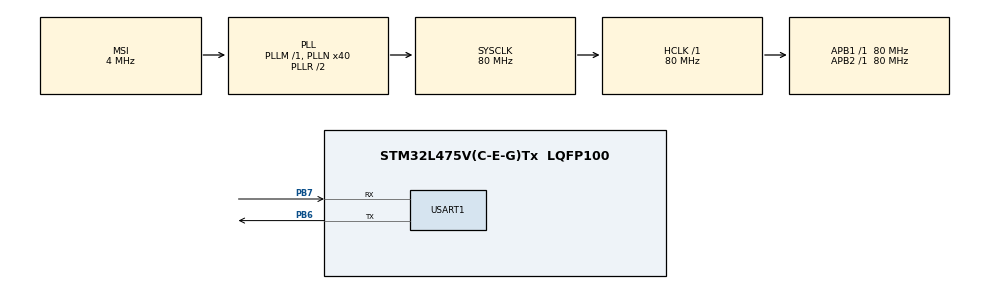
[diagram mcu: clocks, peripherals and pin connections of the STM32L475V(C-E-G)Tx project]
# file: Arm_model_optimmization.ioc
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Mcu.Family=STM32L4
Mcu.Name=STM32L475V(C-E-G)Tx
Mcu.Package=LQFP100
NVIC.PriorityGroup=NVIC_PRIORITYGROUP_4
PA13\ (JTMS-SWDIO).Mode=Trace_Asynchronous_SW
PA13\ (JTMS-SWDIO).Signal=SYS_JTMS-SWDIO
PA14\ (JTCK-SWCLK).Mode=Trace_Asynchronous_SW
PA14\ (JTCK-SWCLK).Signal=SYS_JTCK-SWCLK
PB3\ (JTDO-TRACESWO).Mode=Trace_Asynchronous_SW
PB3\ (JTDO-TRACESWO).Signal=SYS_JTDO-SWO
PB6.Mode=Asynchronous
PB6.Signal=USART1_TX
PB7.Mode=Asynchronous
PB7.Signal=USART1_RX
PH0-OSC_IN\ (PH0).Mode=HSE-External-Oscillator
PH0-OSC_IN\ (PH0).Signal=RCC_OSC_IN
PH1-OSC_OUT\ (PH1).Mode=HSE-External-Oscillator
PH1-OSC_OUT\ (PH1).Signal=RCC_OSC_OUT
ProjectManager.HeapSize=0x800
ProjectManager.StackSize=0x800
ProjectManager.TargetToolchain=STM32CubeIDE
RCC.ADCFreq_Value=48000000
RCC.AHBFreq_Value=80000000
RCC.APB1Freq_Value=80000000
RCC.APB1TimFreq_Value=80000000
RCC.APB2Freq_Value=80000000
RCC.APB2TimFreq_Value=80000000
RCC.CortexFreq_Value=80000000
RCC.HCLKFreq_Value=80000000
RCC.HSE_VALUE=8000000
RCC.HSI_VALUE=16000000
RCC.MSI_VALUE=4000000
RCC.PLLN=40
RCC.PLLSAI1N=24
RCC.SYSCLKFreq_VALUE=80000000
RCC.SYSCLKSource=RCC_SYSCLKSOURCE_PLLCLK
RCC.USBFreq_Value=48000000
RCC.VCOOutputFreq_Value=160000000
STMicroelectronics.X-CUBE-AI.10.2.0.ActivationBufferSizeList=57044
STMicroelectronics.X-CUBE-AI.10.2.0.ActivationBuffers=pool0
STMicroelectronics.X-CUBE-AI.10.2.0.ActivationNames=pool0
STMicroelectronics.X-CUBE-AI.10.2.0.ActivationSizes=AI_NETWORK_DATA_ACTIVATION_1_SIZE
STMicroelectronics.X-CUBE-AI.10.2.0.ApplicationCcDeviceJjApplication=SystemPerformance
STMicroelectronics.X-CUBE-AI.10.2.0.BSP.number=1
STMicroelectronics.X-CUBE-AI.10.2.0.HeapSize=0x800
STMicroelectronics.X-CUBE-AI.10.2.0.InternalRamActivationBufferMaxSize=AI_NETWORK_DATA_ACTIVATIONS_SIZE
STMicroelectronics.X-CUBE-AI.10.2.0.LatestDirectoryUsed-4751c7fde2dbf1a05914dd5fdbb3a8e7d666a6bb74f4718387b990bd9b3825d4=D\:\\1vidamuyarchi\\arm_example
STMicroelectronics.X-CUBE-AI.10.2.0.MaximumNumberOfInputLayer=1
STMicroelectronics.X-CUBE-AI.10.2.0.MaximumNumberOfOutputLayer=1
STMicroelectronics.X-CUBE-AI.10.2.0.MaximumSizeOfInputLayer=1
STMicroelectronics.X-CUBE-AI.10.2.0.MaximumSizeOfOutputLayer=1
STMicroelectronics.X-CUBE-AI.10.2.0.ModelActualCompression-4751c7fde2dbf1a05914dd5fdbb3a8e7d666a6bb74f4718387b990bd9b3825d4=0.0
STMicroelectronics.X-CUBE-AI.10.2.0.ModelCompression-4751c7fde2dbf1a05914dd5fdbb3a8e7d666a6bb74f4718387b990bd9b3825d4=None
STMicroelectronics.X-CUBE-AI.10.2.0.ModelFlashOccupation-4751c7fde2dbf1a05914dd5fdbb3a8e7d666a6bb74f4718387b990bd9b3825d4=110508
STMicroelectronics.X-CUBE-AI.10.2.0.ModelHashList=4751c7fde2dbf1a05914dd5fdbb3a8e7d666a6bb74f4718387b990bd9b3825d4
STMicroelectronics.X-CUBE-AI.10.2.0.ModelKind-4751c7fde2dbf1a05914dd5fdbb3a8e7d666a6bb74f4718387b990bd9b3825d4=TFLITE
STMicroelectronics.X-CUBE-AI.10.2.0.ModelMacc-4751c7fde2dbf1a05914dd5fdbb3a8e7d666a6bb74f4718387b990bd9b3825d4=2737536
STMicroelectronics.X-CUBE-AI.10.2.0.ModelName-4751c7fde2dbf1a05914dd5fdbb3a8e7d666a6bb74f4718387b990bd9b3825d4=network
STMicroelectronics.X-CUBE-AI.10.2.0.ModelNameList=network
STMicroelectronics.X-CUBE-AI.10.2.0.ModelRamOccupation-4751c7fde2dbf1a05914dd5fdbb3a8e7d666a6bb74f4718387b990bd9b3825d4=57044
STMicroelectronics.X-CUBE-AI.10.2.0.ModelStructureFile-4751c7fde2dbf1a05914dd5fdbb3a8e7d666a6bb74f4718387b990bd9b3825d4=/D\:/1vidamuyarchi/arm_example/kws_ref_model_float32.tflite
STMicroelectronics.X-CUBE-AI.10.2.0.ModelType-4751c7fde2dbf1a05914dd5fdbb3a8e7d666a6bb74f4718387b990bd9b3825d4=STM32Cube.AI MCU runtime
STMicroelectronics.X-CUBE-AI.10.2.0.ReadyForCodeGeneration=true
STMicroelectronics.X-CUBE-AI.10.2.0.StackSize=0x800
STMicroelectronics.X-CUBE-AI.10.2.0.WorkingBufferStartAddrList=0xFFFFFFFF
STMicroelectronics.X-CUBE-AI.10.2.0.XAaCUBEAaAICcArtificialOoIntelligenceJjCore=true
STMicroelectronics.X-CUBE-AI.10.2.0.copyWeightToRam=false
STMicroelectronics.X-CUBE-AI.10.2.0.customLayerConfigEnabled=false
STMicroelectronics.X-CUBE-AI.10.2.0.noOnnxIoTranspose=false
STMicroelectronics.X-CUBE-AI.10.2.0.useInputAllocation=true
STMicroelectronics.X-CUBE-AI.10.2.0.useOutputAllocation=true
STMicroelectronics.X-CUBE-AI.10.2.00.BSP.STBoard=false
STMicroelectronics.X-CUBE-AI.10.2.00.BSP.api=Unknown
STMicroelectronics.X-CUBE-AI.10.2.00.BSP.condition=\!SEMDeviceJjApplicationJjApplicationTemplate
STMicroelectronics.X-CUBE-AI.10.2.00.BSP.instance=USART1
STMicroelectronics.X-CUBE-AI.10.2.00.BSP.ip=USART
STMicroelectronics.X-CUBE-AI.10.2.00.BSP.mode=Asynchronous
STMicroelectronics.X-CUBE-AI.10.2.00.BSP.name=COM Port
STMicroelectronics.X-CUBE-AI.10.2.00.BSP.solution=USART1
USART1.VirtualMode-Asynchronous=VM_ASYNC
VP_STMicroelectronics.X-CUBE-AI_VS_ArtificialOoIntelligenceJjXAaCUBEAaAI_10.2.0.Mode=ArtificialOoIntelligenceJjXAaCUBEAaAI
VP_STMicroelectronics.X-CUBE-AI_VS_DeviceJjApplication_10.2.0.Mode=DeviceJjApplication
board=B-L475E-IOT01A1

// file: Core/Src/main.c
/* USER CODE BEGIN Header */
/**
  ******************************************************************************
  * @file           : main.c
  * @brief          : Main program body
  ******************************************************************************
  * @attention
  *
  * Copyright (c) 2026 STMicroelectronics.
  * All rights reserved.
  *
  * This software is licensed under terms that can be found in the LICENSE file
  * in the root directory of this software component.
  * If no LICENSE file comes with this software, it is provided AS-IS.
  *
  ******************************************************************************
  */
/* USER CODE END Header */
#include "main.h"
#include "gpio.h"
#include "app_x-cube-ai.h"

/* USER CODE BEGIN Includes */
#include "usart.h"
#include <stdio.h>
#include <string.h>

extern UART_HandleTypeDef huart1;

int __io_putchar(int ch)
{
	ITM_SendChar(ch);
    return ch;

}

/* USER CODE END Includes */

void SystemClock_Config(void);

int main(void)
{

  /* MCU Configuration--------------------------------------------------------*/

  /* Reset of all peripherals, Initializes the Flash interface and the Systick. */
  HAL_Init();

  /* Configure the system clock */
  SystemClock_Config();

  /* Initialize all configured peripherals */
  MX_GPIO_Init();
  MX_USART1_UART_Init();
  MX_X_CUBE_AI_Init();

  /* Infinite loop */
  while (1)
  {

  MX_X_CUBE_AI_Process();
  }
}

void SystemClock_Config(void)
{
  RCC_OscInitTypeDef RCC_OscInitStruct = {0};
  RCC_ClkInitTypeDef RCC_ClkInitStruct = {0};

  /** Configure the main internal regulator output voltage
  */
  if (HAL_PWREx_ControlVoltageScaling(PWR_REGULATOR_VOLTAGE_SCALE1) != HAL_OK)
  {
    Error_Handler();
  }

  /** Initializes the RCC Oscillators according to the specified parameters
  * in the RCC_OscInitTypeDef structure.
  */
  RCC_OscInitStruct.OscillatorType = RCC_OSCILLATORTYPE_MSI;
  RCC_OscInitStruct.MSIState = RCC_MSI_ON;
  RCC_OscInitStruct.MSICalibrationValue = 0;
  RCC_OscInitStruct.MSIClockRange = RCC_MSIRANGE_6;
  RCC_OscInitStruct.PLL.PLLState = RCC_PLL_ON;
  RCC_OscInitStruct.PLL.PLLSource = RCC_PLLSOURCE_MSI;
  RCC_OscInitStruct.PLL.PLLM = 1;
  RCC_OscInitStruct.PLL.PLLN = 40;
  RCC_OscInitStruct.PLL.PLLP = RCC_PLLP_DIV7;
  RCC_OscInitStruct.PLL.PLLQ = RCC_PLLQ_DIV2;
  RCC_OscInitStruct.PLL.PLLR = RCC_PLLR_DIV2;
  if (HAL_RCC_OscConfig(&RCC_OscInitStruct) != HAL_OK)
  {
    Error_Handler();
  }

  /** Initializes the CPU, AHB and APB buses clocks
  */
  RCC_ClkInitStruct.ClockType = RCC_CLOCKTYPE_HCLK|RCC_CLOCKTYPE_SYSCLK
                              |RCC_CLOCKTYPE_PCLK1|RCC_CLOCKTYPE_PCLK2;
  RCC_ClkInitStruct.SYSCLKSource = RCC_SYSCLKSOURCE_PLLCLK;
  RCC_ClkInitStruct.AHBCLKDivider = RCC_SYSCLK_DIV1;
  RCC_ClkInitStruct.APB1CLKDivider = RCC_HCLK_DIV1;
  RCC_ClkInitStruct.APB2CLKDivider = RCC_HCLK_DIV1;

  if (HAL_RCC_ClockConfig(&RCC_ClkInitStruct, FLASH_LATENCY_4) != HAL_OK)
  {
    Error_Handler();
  }
}

void Error_Handler(void)
{
  __disable_irq();
  while (1)
  {
  }
}
